# EZR32WG330F256R68 register map
File version: 5.2.1
Registers are 32-bit, read-write, reset 0x0 unless marked. A register's access mark holds for its fields unless they carry their own. Offsets are from the block's base; [hi:lo] are bit positions; {n}, {i} and the like mark numbered series.

## RMU
Base 0x400CA000
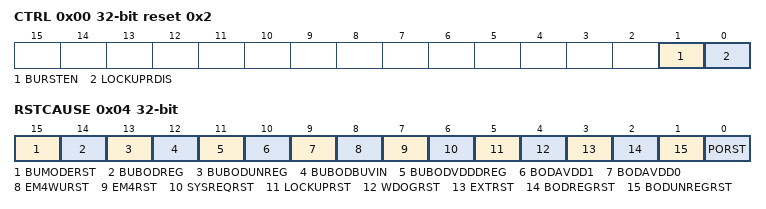
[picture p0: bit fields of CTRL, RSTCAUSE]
0x00 CTRL reset 0x2 — Control Register
  [1] BURSTEN — Backup domain reset enable
  [0] LOCKUPRDIS — Lockup Reset Disable
0x04 RSTCAUSE ro — Reset Cause Register
  [15] BUMODERST — Backup mode reset
  [14] BUBODREG — Backup Brown Out Detector Regulated Domain
  [13] BUBODUNREG — Backup Brown Out Detector Unregulated Domain
  [12] BUBODBUVIN — Backup Brown Out Detector, BU_VIN
  [11] BUBODVDDDREG — Backup Brown Out Detector, VDD_DREG
  [10] BODAVDD1 — AVDD1 Bod Reset
  [9] BODAVDD0 — AVDD0 Bod Reset
  [8] EM4WURST — EM4 Wake-up Reset
  [7] EM4RST — EM4 Reset
  [6] SYSREQRST — System Request Reset
  [5] LOCKUPRST — LOCKUP Reset
  [4] WDOGRST — Watchdog Reset
  [3] EXTRST — External Pin Reset
  [2] BODREGRST — Brown Out Detector Regulated Domain Reset
  [1] BODUNREGRST — Brown Out Detector Unregulated Domain Reset
  [0] PORST — Power On Reset
0x08 CMD wo — Command Register
  [0] RCCLR — Reset Cause Clear

## FPUEH
Base 0x400C1C00
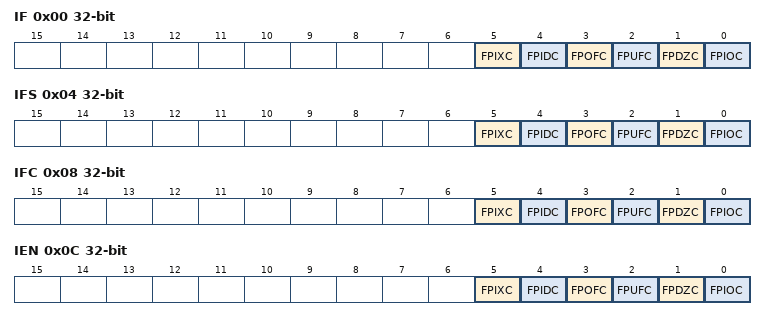
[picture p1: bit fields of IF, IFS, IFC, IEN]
0x00 IF ro — Interrupt Flag Register
  [5] FPIXC — FPU inexact exception
  [4] FPIDC — FPU input denormal exception
  [3] FPOFC — FPU overflow exception
  [2] FPUFC — FPU underflow exception
  [1] FPDZC — FPU divide-by-zero exception
  [0] FPIOC — FPU invalid operation
0x04 IFS wo — Interrupt Flag Set Register
  [5] FPIXC — Set FPIXC Interrupt Flag
  [4] FPIDC — Set FPIDC Interrupt Flag
  [3] FPOFC — Set FPOFC Interrupt Flag
  [2] FPUFC — Set FPUFC Interrupt Flag
  [1] FPDZC — Set FPDZC Interrupt Flag
  [0] FPIOC — Set FPIOC Interrupt Flag
0x08 IFC — Interrupt Flag Clear Register
  [5] FPIXC — Clear FPIXC Interrupt Flag
  [4] FPIDC — Clear FPIDC Interrupt Flag
  [3] FPOFC — Clear FPOFC Interrupt Flag
  [2] FPUFC — Clear FPUFC Interrupt Flag
  [1] FPDZC — Clear FPDZC Interrupt Flag
  [0] FPIOC — Clear FPIOC Interrupt Flag
0x0C IEN — Interrupt Enable Register
  [5] FPIXC — FPIXC Interrupt Enable
  [4] FPIDC — FPIDC Interrupt Enable
  [3] FPOFC — FPOFC Interrupt Enable
  [2] FPUFC — FPUFC Interrupt Enable
  [1] FPDZC — FPDZC Interrupt Enable
  [0] FPIOC — FPIOC Interrupt Enable

## ACMP0
Base 0x40001000
Same registers: ACMP1 0x40001400
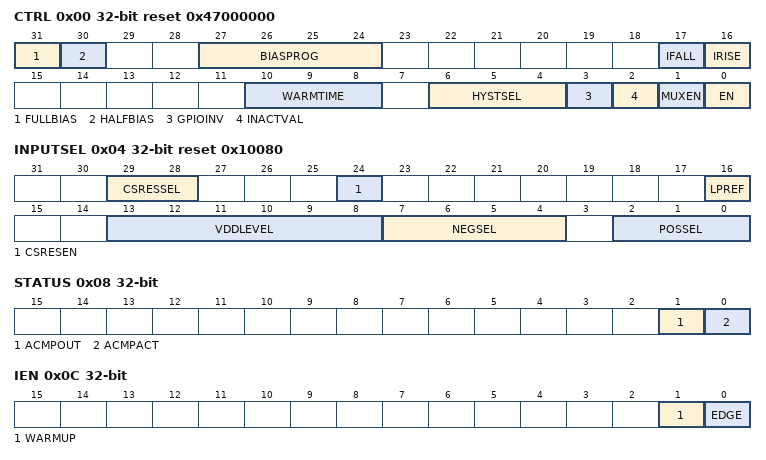
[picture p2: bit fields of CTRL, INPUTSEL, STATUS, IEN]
0x00 CTRL reset 0x47000000 — Control Register
  [31] FULLBIAS — Full Bias Current
  [30] HALFBIAS — Half Bias Current
  [27:24] BIASPROG — Bias Configuration
  [17] IFALL — Falling Edge Interrupt Sense
  [16] IRISE — Rising Edge Interrupt Sense
  [10:8] WARMTIME — Warm-up Time
    0=4CYCLES (4 HFPERCLK cycles.); 1=8CYCLES (8 HFPERCLK cycles.); 2=16CYCLES (16 HFPERCLK cycles.); 3=32CYCLES (32 HFPERCLK cycles.); 4=64CYCLES (64 HFPERCLK cycles.); 5=128CYCLES (128 HFPERCLK cycles.); 6=256CYCLES (256 HFPERCLK cycles.); 7=512CYCLES (512 HFPERCLK cycles.)
  [6:4] HYSTSEL — Hysteresis Select
    0=HYST0 (No hysteresis.); 1=HYST1 (~15 mV hysteresis.); 2=HYST2 (~22 mV hysteresis.); 3=HYST3 (~29 mV hysteresis.); 4=HYST4 (~36 mV hysteresis.); 5=HYST5 (~43 mV hysteresis.); 6=HYST6 (~50 mV hysteresis.); 7=HYST7 (~57 mV hysteresis.)
  [3] GPIOINV — Comparator GPIO Output Invert
  [2] INACTVAL — Inactive Value
  [1] MUXEN — Input Mux Enable
  [0] EN — Analog Comparator Enable
0x04 INPUTSEL reset 0x10080 — Input Selection Register
  [29:28] CSRESSEL — Capacitive Sense Mode Internal Resistor Select
    {v}=RES{v} (Internal capacitive sense resistor value {v}.) (v=0..3)
  [24] CSRESEN — Capacitive Sense Mode Internal Resistor Enable
  [16] LPREF — Low Power Reference Mode
  [13:8] VDDLEVEL — VDD Reference Level
  [7:4] NEGSEL — Negative Input Select
    {v}=CH{v} (Channel {v} as negative input.) (v=0..7); 8=1V25 (1.25 V as negative input.); 9=2V5 (2.5 V as negative input.); 10=VDD (Scaled VDD as negative input.); 11=CAPSENSE (Capacitive sense mode.); 12=DAC0CH0 (DAC0 channel 0.); 13=DAC0CH1 (DAC0 channel 1.)
  [2:0] POSSEL — Positive Input Select
    {v}=CH{v} (Channel {v} as positive input.) (v=0..7)
0x08 STATUS ro
  [1] ACMPOUT — Analog Comparator Output
  [0] ACMPACT — Analog Comparator Active
0x0C IEN — Interrupt Enable Register
  [1] WARMUP — Warm-up Interrupt Enable
  [0] EDGE — Edge Trigger Interrupt Enable
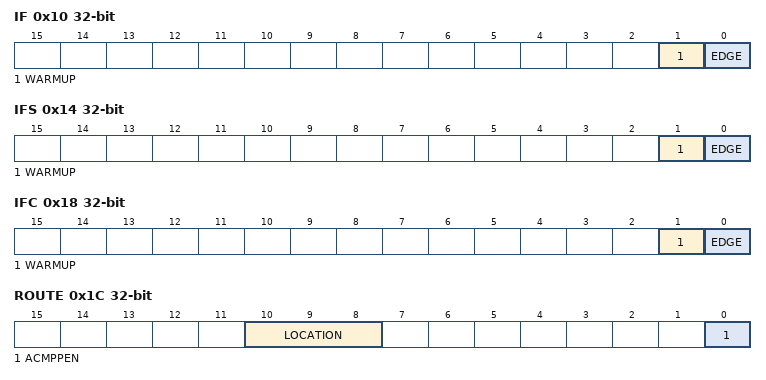
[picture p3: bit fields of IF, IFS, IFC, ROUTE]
0x10 IF ro — Interrupt Flag Register
  [1] WARMUP — Warm-up Interrupt Flag
  [0] EDGE — Edge Triggered Interrupt Flag
0x14 IFS wo — Interrupt Flag Set Register
  [1] WARMUP — Warm-up Interrupt Flag Set
  [0] EDGE — Edge Triggered Interrupt Flag Set
0x18 IFC wo — Interrupt Flag Clear Register
  [1] WARMUP — Warm-up Interrupt Flag Clear
  [0] EDGE — Edge Triggered Interrupt Flag Clear
0x1C ROUTE — I/O Routing Register
  [10:8] LOCATION — I/O Location
    0=LOC0 (Location 0); 1=LOC1 (Location 1); 2=LOC2 (Location 2)
  [0] ACMPPEN — ACMP Output Pin Enable
